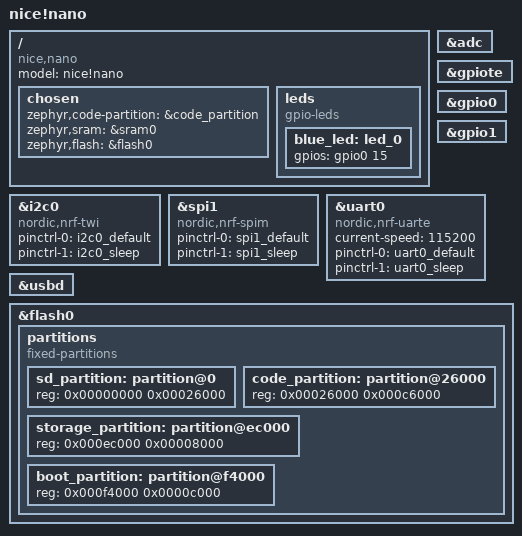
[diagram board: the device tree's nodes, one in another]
/*
 * Local nice!nano board base for Zephyr applications outside ZMK.
 */

/dts-v1/;
#include <nordic/nrf52840_qiaa.dtsi>
#include "nice_nano-pinctrl.dtsi"
#include "arduino_pro_micro_pins.dtsi"

/ {
	model = "nice!nano";
	compatible = "nice,nano";

	chosen {
		zephyr,code-partition = &code_partition;
		zephyr,sram = &sram0;
		zephyr,flash = &flash0;
	};

	leds {
		compatible = "gpio-leds";
		blue_led: led_0 {
			gpios = <&gpio0 15 GPIO_ACTIVE_HIGH>;
		};
	};
};

&adc {
	status = "okay";
};

&gpiote {
	status = "okay";
};

&gpio0 {
	status = "okay";
};

&gpio1 {
	status = "okay";
};

&i2c0 {
	compatible = "nordic,nrf-twi";
	pinctrl-0 = <&i2c0_default>;
	pinctrl-1 = <&i2c0_sleep>;
	pinctrl-names = "default", "sleep";
	status = "okay";
};

&spi1 {
	compatible = "nordic,nrf-spim";
	pinctrl-0 = <&spi1_default>;
	pinctrl-1 = <&spi1_sleep>;
	pinctrl-names = "default", "sleep";
	status = "okay";
};

&uart0 {
	compatible = "nordic,nrf-uarte";
	current-speed = <115200>;
	pinctrl-0 = <&uart0_default>;
	pinctrl-1 = <&uart0_sleep>;
	pinctrl-names = "default", "sleep";
	status = "okay";
};

&usbd {
	status = "okay";
};

&flash0 {
	partitions {
		compatible = "fixed-partitions";
		#address-cells = <1>;
		#size-cells = <1>;

		sd_partition: partition@0 {
			reg = <0x00000000 0x00026000>;
		};

		code_partition: partition@26000 {
			reg = <0x00026000 0x000c6000>;
		};

		storage_partition: partition@ec000 {
			reg = <0x000ec000 0x00008000>;
		};

		boot_partition: partition@f4000 {
			reg = <0x000f4000 0x0000c000>;
		};
	};
};
